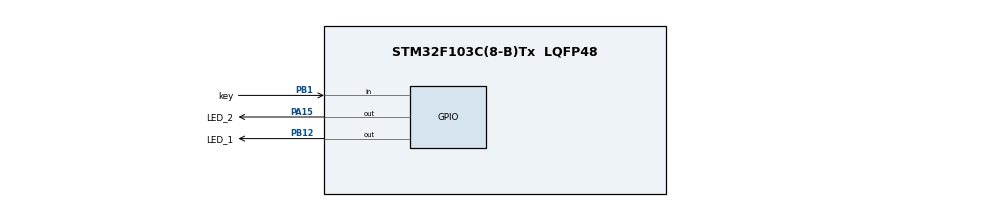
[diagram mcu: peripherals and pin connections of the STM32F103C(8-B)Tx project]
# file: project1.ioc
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FREERTOS.Queues01=queuemotor,16,uint8_t,0,Dynamic,NULL,NULL
FREERTOS.Tasks01=TaskMotor,24,128,StartDefaultTask,Default,NULL,Dynamic,NULL,NULL;TaskSensor,16,128,StartTask02,Default,NULL,Dynamic,NULL,NULL;TaskHeartbeat,8,128,StartTask03,Default,NULL,Dynamic,NULL,NULL
Mcu.Family=STM32F1
Mcu.Name=STM32F103C(8-B)Tx
Mcu.Package=LQFP48
NVIC.PriorityGroup=NVIC_PRIORITYGROUP_4
NVIC.TIM1_UP_IRQn=true\:15\:0\:false\:false\:true\:false\:false\:true\:true
NVIC.TimeBase=TIM1_UP_IRQn
NVIC.TimeBaseIP=TIM1
PA13.Mode=Serial_Wire
PA13.Signal=SYS_JTMS-SWDIO
PA14.Mode=Serial_Wire
PA14.Signal=SYS_JTCK-SWCLK
PA15.GPIO_Label=LED_2
PA15.Signal=GPIO_Output
PB1.GPIO_Label=key
PB1.GPIO_PuPd=GPIO_PULLUP
PB1.Signal=GPIO_Input
PB12.GPIO_Label=LED_1
PB12.Signal=GPIO_Output
ProjectManager.HeapSize=0x200
ProjectManager.StackSize=0x400
ProjectManager.TargetToolchain=MDK-ARM V5.32
RCC.APB1Freq_Value=8000000
RCC.APB2Freq_Value=8000000
VP_FREERTOS_VS_CMSIS_V2.Mode=CMSIS_V2
VP_SYS_VS_tim1.Mode=TIM1
board=custom

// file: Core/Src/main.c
/* USER CODE BEGIN Header */
/**
  ******************************************************************************
  * @file           : main.c
  * @brief          : Main program body
  ******************************************************************************
  * @attention
  *
  * Copyright (c) 2026 STMicroelectronics.
  * All rights reserved.
  *
  * This software is licensed under terms that can be found in the LICENSE file
  * in the root directory of this software component.
  * If no LICENSE file comes with this software, it is provided AS-IS.
  *
  ******************************************************************************
  */
/* USER CODE END Header */
#include "main.h"

/* USER CODE BEGIN Includes */
#include "FreeRTOS.h"
#include "task.h"
#include "queue.h"
/* USER CODE END Includes */

void SystemClock_Config(void);
static void MX_GPIO_Init(void);
extern void MX_FREERTOS_Init(void);

int main(void)
{
  /* MCU Configuration--------------------------------------------------------*/
  HAL_Init();
  SystemClock_Config();
  MX_GPIO_Init();

  /* USER CODE BEGIN 2 */
  // 这是我们自己的初始化，不再调用任何 CubeMX 的 RTOS 代码
  MX_FREERTOS_Init();
  // 启动调度器，从此以后，while(1) 将永远不会被执行
  vTaskStartScheduler();
  /* USER CODE END 2 */

  /* We should never get here as control is now taken by the scheduler */
  while (1)
  {
  }
}

void SystemClock_Config(void)
{
  RCC_OscInitTypeDef RCC_OscInitStruct = {0};
  RCC_ClkInitTypeDef RCC_ClkInitStruct = {0};

  RCC_OscInitStruct.OscillatorType = RCC_OSCILLATORTYPE_HSI;
  RCC_OscInitStruct.HSIState = RCC_HSI_ON;
  RCC_OscInitStruct.HSICalibrationValue = RCC_HSICALIBRATION_DEFAULT;
  RCC_OscInitStruct.PLL.PLLState = RCC_PLL_NONE;
  if (HAL_RCC_OscConfig(&RCC_OscInitStruct) != HAL_OK)
  {
    Error_Handler();
  }

  RCC_ClkInitStruct.ClockType = RCC_CLOCKTYPE_HCLK|RCC_CLOCKTYPE_SYSCLK
                              |RCC_CLOCKTYPE_PCLK1|RCC_CLOCKTYPE_PCLK2;
  RCC_ClkInitStruct.SYSCLKSource = RCC_SYSCLKSOURCE_HSI;
  RCC_ClkInitStruct.AHBCLKDivider = RCC_SYSCLK_DIV1;
  RCC_ClkInitStruct.APB1CLKDivider = RCC_HCLK_DIV1;
  RCC_ClkInitStruct.APB2CLKDivider = RCC_HCLK_DIV1;

  if (HAL_RCC_ClockConfig(&RCC_ClkInitStruct, FLASH_LATENCY_0) != HAL_OK)
  {
    Error_Handler();
  }
}

static void MX_GPIO_Init(void)
{
  GPIO_InitTypeDef GPIO_InitStruct = {0};

  __HAL_RCC_GPIOB_CLK_ENABLE();
  __HAL_RCC_GPIOA_CLK_ENABLE();

  HAL_GPIO_WritePin(GPIOB, GPIO_PIN_12, GPIO_PIN_RESET);
  HAL_GPIO_WritePin(GPIOA, GPIO_PIN_15, GPIO_PIN_RESET);

  /*Configure GPIO pin : PB1 (按键) */
  GPIO_InitStruct.Pin = GPIO_PIN_1;
  GPIO_InitStruct.Mode = GPIO_MODE_INPUT;
  GPIO_InitStruct.Pull = GPIO_PULLUP;
  HAL_GPIO_Init(GPIOB, &GPIO_InitStruct);

  /*Configure GPIO pin : PB12 (红灯) */
  GPIO_InitStruct.Pin = GPIO_PIN_12;
  GPIO_InitStruct.Mode = GPIO_MODE_OUTPUT_PP;
  GPIO_InitStruct.Pull = GPIO_NOPULL;
  GPIO_InitStruct.Speed = GPIO_SPEED_FREQ_LOW;
  HAL_GPIO_Init(GPIOB, &GPIO_InitStruct);

  /*Configure GPIO pin : PA15 (绿灯) */
  GPIO_InitStruct.Pin = GPIO_PIN_15;
  GPIO_InitStruct.Mode = GPIO_MODE_OUTPUT_PP;
  GPIO_InitStruct.Pull = GPIO_NOPULL;
  GPIO_InitStruct.Speed = GPIO_SPEED_FREQ_LOW;
  HAL_GPIO_Init(GPIOA, &GPIO_InitStruct);
}

void Error_Handler(void)
{
  __disable_irq();
  while (1)
  {
  }
}

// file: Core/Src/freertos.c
/* USER CODE BEGIN Header */
/**
  ******************************************************************************
  * File Name          : freertos.c
  * Description        : Code for freertos applications
  ******************************************************************************
  * @attention
  *
  * Copyright (c) 2026 STMicroelectronics.
  * All rights reserved.
  *
  * This software is licensed under terms that can be found in the LICENSE file
  * in the root directory of this software component.
  * If no LICENSE file comes with this software, it is provided AS-IS.
  *
  ******************************************************************************
  */
/* USER CODE END Header */

#include "FreeRTOS.h"
#include "queue.h"
#include "task.h"
#include "main.h"

/* USER CODE BEGIN Variables */
QueueHandle_t queueMotorHandle;
/* USER CODE END Variables */

/* USER CODE BEGIN FunctionPrototypes */
void TaskSensor(void *argument);
void TaskMotor(void *argument);
void TaskHeartbeat(void *argument);
/* USER CODE END FunctionPrototypes */

/* USER CODE BEGIN Application */

// 1. 初始化函数
void MX_FREERTOS_Init(void)
{
    // 创建队列
    queueMotorHandle = xQueueCreate(5, sizeof(uint8_t));

    // 创建任务
    xTaskCreate(TaskSensor, "Sensor", 128, NULL, 3, NULL);
    xTaskCreate(TaskMotor, "Motor", 128, NULL, 3, NULL);
    xTaskCreate(TaskHeartbeat, "Heartbeat", 64, NULL, 1, NULL);
}

// 2. 传感器任务
void TaskSensor(void *argument)
{
    uint8_t sensor_count = 0;
    uint8_t msg = 1;
    for(;;)
    {
        if(HAL_GPIO_ReadPin(GPIOB, GPIO_PIN_1) == GPIO_PIN_RESET)
        {
            vTaskDelay(20 / portTICK_PERIOD_MS);
            if(HAL_GPIO_ReadPin(GPIOB, GPIO_PIN_1) == GPIO_PIN_RESET)
            {
                sensor_count++;
                while(HAL_GPIO_ReadPin(GPIOB, GPIO_PIN_1) == GPIO_PIN_RESET);
                vTaskDelay(20 / portTICK_PERIOD_MS);
            }
        }

        if(sensor_count >= 5)
        {
            xQueueSend(queueMotorHandle, &msg, 0);
            sensor_count = 0;
        }

        vTaskDelay(10 / portTICK_PERIOD_MS);
    }
}

// 3. 电机任务
void TaskMotor(void *argument)
{
    uint8_t received_msg;
    for(;;)
    {
        if(xQueueReceive(queueMotorHandle, &received_msg, portMAX_DELAY) == pdTRUE)
        {
            for(int i = 0; i < 3; i++)
            {
                HAL_GPIO_WritePin(GPIOA, GPIO_PIN_15, GPIO_PIN_SET);
                vTaskDelay(200 / portTICK_PERIOD_MS);
                HAL_GPIO_WritePin(GPIOA, GPIO_PIN_15, GPIO_PIN_RESET);
                vTaskDelay(200 / portTICK_PERIOD_MS);
            }
        }
    }
}

// 4. 心跳任务
void TaskHeartbeat(void *argument)
{
    for(;;)
    {
        HAL_GPIO_TogglePin(GPIOB, GPIO_PIN_12);
        vTaskDelay(1000 / portTICK_PERIOD_MS);
    }
}

/* USER CODE END Application */
